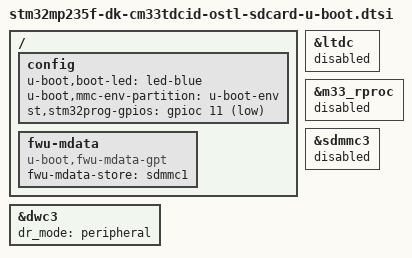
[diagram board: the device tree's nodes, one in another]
// SPDX-License-Identifier: (GPL-2.0-only OR BSD-3-Clause)
/*
 * Copyright (C) STMicroelectronics 2025 - All Rights Reserved
 */

#include "stm32mp23-u-boot.dtsi"

/* Remove USB Type-C related nodes */
/delete-node/ &i2c1;
/delete-node/ &ucpd;

/ {
	config {
		u-boot,boot-led = "led-blue";
		u-boot,mmc-env-partition = "u-boot-env";
		st,stm32prog-gpios = <&gpioc 11 (GPIO_ACTIVE_LOW | GPIO_PULL_UP)>;
	};

	fwu-mdata {
		compatible = "u-boot,fwu-mdata-gpt";
		fwu-mdata-store = <&sdmmc1>;
	};
};

&dwc3 {
	dr_mode = "peripheral";
	/delete-node/ port;
};

&ltdc {
	status = "disabled";
};

&m33_rproc {
	status = "disabled";
};

&sdmmc3 {
	status = "disabled";
};
